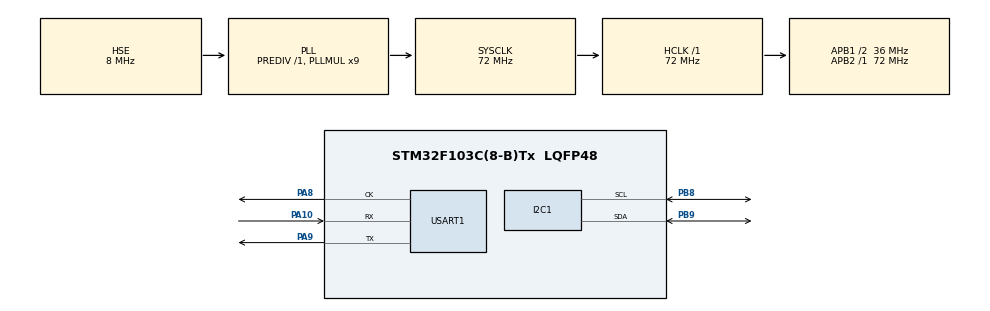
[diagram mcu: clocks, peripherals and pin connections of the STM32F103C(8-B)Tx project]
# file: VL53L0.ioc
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I2C1.I2C_Mode=I2C_Fast
Mcu.Family=STM32F1
Mcu.Name=STM32F103C(8-B)Tx
Mcu.Package=LQFP48
NVIC.PriorityGroup=NVIC_PRIORITYGROUP_4
PA10.Mode=Synchronous
PA10.Signal=USART1_RX
PA13.Mode=Serial_Wire
PA13.Signal=SYS_JTMS-SWDIO
PA14.Mode=Serial_Wire
PA14.Signal=SYS_JTCK-SWCLK
PA8.Mode=Synchronous
PA8.Signal=USART1_CK
PA9.Mode=Synchronous
PA9.Signal=USART1_TX
PB8.Mode=I2C
PB8.Signal=I2C1_SCL
PB9.Mode=I2C
PB9.Signal=I2C1_SDA
PD0-OSC_IN.Mode=HSE-External-Oscillator
PD0-OSC_IN.Signal=RCC_OSC_IN
PD1-OSC_OUT.Mode=HSE-External-Oscillator
PD1-OSC_OUT.Signal=RCC_OSC_OUT
ProjectManager.HeapSize=0x200
ProjectManager.StackSize=0x400
ProjectManager.TargetToolchain=MDK-ARM V5.27
RCC.AHBFreq_Value=72000000
RCC.APB1CLKDivider=RCC_HCLK_DIV2
RCC.APB1Freq_Value=36000000
RCC.APB1TimFreq_Value=72000000
RCC.APB2Freq_Value=72000000
RCC.APB2TimFreq_Value=72000000
RCC.HCLKFreq_Value=72000000
RCC.PLLMUL=RCC_PLL_MUL9
RCC.PLLSourceVirtual=RCC_PLLSOURCE_HSE
RCC.SYSCLKFreq_VALUE=72000000
RCC.SYSCLKSource=RCC_SYSCLKSOURCE_PLLCLK
RCC.USBFreq_Value=72000000
USART1.VirtualMode=VM_SYNC
board=custom

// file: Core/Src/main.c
/* USER CODE BEGIN Header */
/**
  ******************************************************************************
  * @file           : main.c
  * @brief          : Main program body
  ******************************************************************************
  * @attention
  *
  * <h2><center>&copy; Copyright (c) 2021 STMicroelectronics.
  * All rights reserved.</center></h2>
  *
  * This software component is licensed by ST under BSD 3-Clause license,
  * the "License"; You may not use this file except in compliance with the
  * License. You may obtain a copy of the License at:
  *                        opensource.org/licenses/BSD-3-Clause
  *
  ******************************************************************************
  */
/* USER CODE END Header */
#include "main.h"

I2C_HandleTypeDef hi2c1;

USART_HandleTypeDef husart1;
GPIO_InitTypeDef a5,a6;
uint8_t mes[4];
void SystemClock_Config(void);
static void MX_GPIO_Init(void);
static void MX_I2C1_Init(void);
static void MX_USART1_Init(void);
void init_both_vl53(void);
void dist_to_mes(void);
/* USER CODE BEGIN PFP */
void marker(uint8_t mes)
{	HAL_USART_Transmit(&husart1,&mes,1,0xFFFF);//маркер
	HAL_Delay(10);}
/* USER CODE END PFP */
uint8_t adr1=0x30,adr2=0x31;

int main(void)
{

  /* MCU Configuration--------------------------------------------------------*/

  /* Reset of all peripherals, Initializes the Flash interface and the Systick. */
  HAL_Init();

  /* Configure the system clock */
  SystemClock_Config();

  /* Initialize all configured peripherals */

  MX_GPIO_Init();
  MX_I2C1_Init();
  MX_USART1_Init();

	//этот пин объявляем для того что бы в момент\
	инициализации мы могли один выключить, тот на\
	котором осается адрес 0x29
	a5.Pin=GPIO_PIN_5;
	a5.Mode=GPIO_MODE_OUTPUT_PP;
	a5.Speed=GPIO_SPEED_FREQ_LOW;
	HAL_GPIO_Init (GPIOA,&a5);
	HAL_GPIO_WritePin(GPIOA,a5.Pin,GPIO_PIN_RESET);
	a6.Pin=GPIO_PIN_6;
	HAL_GPIO_Init (GPIOA,&a6);
	HAL_GPIO_WritePin(GPIOA,a6.Pin,GPIO_PIN_RESET);
	init_both_vl53();
  while (1)
  {
		dist_to_mes();
		HAL_Delay(10);
  }
}

void dist_to_mes()
{

	VL53L0X.address=adr1;
	uint16_t mes1=VL53L0X_readRangeContinuousMillimeters();//VL53L0X_readRangeSingleMillimeters();
	if(VL53L0X.did_timeout==true) {VL53L0X.did_timeout=false;goto m_next;}
	mes[0]=mes1>>2;
	mes[1]=0x20;
	VL53L0X.address=adr2;
	mes1=VL53L0X_readRangeContinuousMillimeters();//VL53L0X_readRangeSingleMillimeters();
	if(VL53L0X.did_timeout==true) {VL53L0X.did_timeout=false;goto m_next;}
	mes[2]=mes1>>2;
	mes[3]=0x0a;
	HAL_USART_Transmit(&husart1,mes,4,0xFFFF);
	m_next:
	HAL_Delay(10);

}

//инициализация обоих датчиков
void init_both_vl53()
{
	//ресетим оба датчика
	HAL_GPIO_WritePin(GPIOA,a6.Pin,GPIO_PIN_RESET);
	HAL_GPIO_WritePin(GPIOA,a5.Pin,GPIO_PIN_RESET);
	HAL_Delay(10);
	HAL_GPIO_WritePin(GPIOA,a6.Pin,GPIO_PIN_SET);
	HAL_GPIO_WritePin(GPIOA,a5.Pin,GPIO_PIN_SET);
	HAL_Delay(10);
	//ресетим оба датчика
	HAL_GPIO_WritePin(GPIOA,a6.Pin,GPIO_PIN_RESET);
	HAL_GPIO_WritePin(GPIOA,a5.Pin,GPIO_PIN_RESET);
	HAL_Delay(10);
	HAL_GPIO_WritePin(GPIOA,a6.Pin,GPIO_PIN_SET);
	HAL_GPIO_WritePin(GPIOA,a5.Pin,GPIO_PIN_SET);
	HAL_Delay(10);
	//активируем первый, ресетим второй
	HAL_GPIO_WritePin(GPIOA,a6.Pin,GPIO_PIN_SET);
	HAL_GPIO_WritePin(GPIOA,a5.Pin,GPIO_PIN_RESET);
	HAL_Delay(10);
	for(int i=1; i<128; i++)
    {
        uint8_t ret = HAL_I2C_IsDeviceReady(&hi2c1, (uint16_t)(i<<1), 3, 5);
				if(ret==HAL_OK) {VL53L0X.address=i;break;}
		}
	//VL53L0X.address=0x29;
	VL53L0X_setAddress(adr1);
	init_VL53L0X();
	HAL_Delay(10);
	VL53L0X_startContinuous(10);
	HAL_Delay(10);
	//включаем второго мсье
	HAL_GPIO_WritePin(GPIOA,a5.Pin,GPIO_PIN_SET);
	HAL_Delay(10);
	for(int i=1; i<128; i++)
    {
        uint8_t ret = HAL_I2C_IsDeviceReady(&hi2c1, (uint16_t)(i<<1), 3, 5);
				if((ret==HAL_OK)&&(i!=adr1)) {VL53L0X.address=i;break;}
		}
	//VL53L0X.address=0x29;
	VL53L0X_setAddress(adr2);
	init_VL53L0X();
	HAL_Delay(10);
	VL53L0X_startContinuous(10);
	HAL_Delay(10);
}

void SystemClock_Config(void)
{
  RCC_OscInitTypeDef RCC_OscInitStruct = {0};
  RCC_ClkInitTypeDef RCC_ClkInitStruct = {0};

  /** Initializes the RCC Oscillators according to the specified parameters
  * in the RCC_OscInitTypeDef structure.
  */
  RCC_OscInitStruct.OscillatorType = RCC_OSCILLATORTYPE_HSE;
  RCC_OscInitStruct.HSEState = RCC_HSE_ON;
  RCC_OscInitStruct.HSEPredivValue = RCC_HSE_PREDIV_DIV1;
  RCC_OscInitStruct.HSIState = RCC_HSI_ON;
  RCC_OscInitStruct.PLL.PLLState = RCC_PLL_ON;
  RCC_OscInitStruct.PLL.PLLSource = RCC_PLLSOURCE_HSE;
  RCC_OscInitStruct.PLL.PLLMUL = RCC_PLL_MUL9;
  if (HAL_RCC_OscConfig(&RCC_OscInitStruct) != HAL_OK)
  {
    Error_Handler();
  }
  /** Initializes the CPU, AHB and APB buses clocks
  */
  RCC_ClkInitStruct.ClockType = RCC_CLOCKTYPE_HCLK|RCC_CLOCKTYPE_SYSCLK
                              |RCC_CLOCKTYPE_PCLK1|RCC_CLOCKTYPE_PCLK2;
  RCC_ClkInitStruct.SYSCLKSource = RCC_SYSCLKSOURCE_PLLCLK;
  RCC_ClkInitStruct.AHBCLKDivider = RCC_SYSCLK_DIV1;
  RCC_ClkInitStruct.APB1CLKDivider = RCC_HCLK_DIV2;
  RCC_ClkInitStruct.APB2CLKDivider = RCC_HCLK_DIV1;

  if (HAL_RCC_ClockConfig(&RCC_ClkInitStruct, FLASH_LATENCY_2) != HAL_OK)
  {
    Error_Handler();
  }
}

static void MX_I2C1_Init(void)
{

  hi2c1.Instance = I2C1;
  hi2c1.Init.ClockSpeed = 400000;
  hi2c1.Init.DutyCycle = I2C_DUTYCYCLE_2;
  hi2c1.Init.OwnAddress1 = 0;
  hi2c1.Init.AddressingMode = I2C_ADDRESSINGMODE_7BIT;
  hi2c1.Init.DualAddressMode = I2C_DUALADDRESS_DISABLE;
  hi2c1.Init.OwnAddress2 = 0;
  hi2c1.Init.GeneralCallMode = I2C_GENERALCALL_DISABLE;
  hi2c1.Init.NoStretchMode = I2C_NOSTRETCH_DISABLE;
  if (HAL_I2C_Init(&hi2c1) != HAL_OK)
  {
    Error_Handler();
  }

}

static void MX_USART1_Init(void)
{

  husart1.Instance = USART1;
  husart1.Init.BaudRate = 115200;
  husart1.Init.WordLength = USART_WORDLENGTH_8B;
  husart1.Init.StopBits = USART_STOPBITS_1;
  husart1.Init.Parity = USART_PARITY_NONE;
  husart1.Init.Mode = USART_MODE_TX_RX;
  husart1.Init.CLKPolarity = USART_POLARITY_LOW;
  husart1.Init.CLKPhase = USART_PHASE_1EDGE;
  husart1.Init.CLKLastBit = USART_LASTBIT_DISABLE;
  if (HAL_USART_Init(&husart1) != HAL_OK)
  {
    Error_Handler();
  }

}

static void MX_GPIO_Init(void)
{

  /* GPIO Ports Clock Enable */
  __HAL_RCC_GPIOD_CLK_ENABLE();
  __HAL_RCC_GPIOA_CLK_ENABLE();
  __HAL_RCC_GPIOB_CLK_ENABLE();

}

void Error_Handler(void)
{
  __disable_irq();
  while (1)
  {
  }
}

/************************ (C) COPYRIGHT STMicroelectronics *****END OF FILE****/
